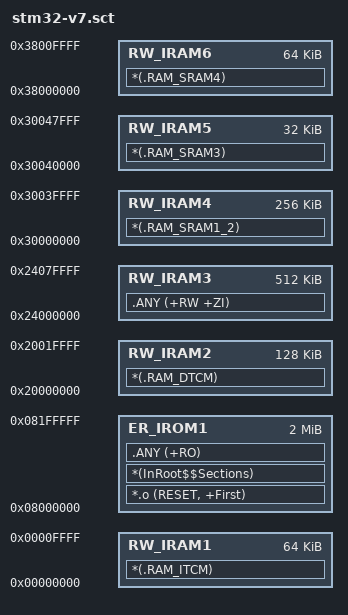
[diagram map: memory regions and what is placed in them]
; *************************************************************
; *** Scatter-Loading Description File generated by uVision ***
; *************************************************************

LR_IROM1 0x08000000 0x00200000  {    ; load region size_region
  ER_IROM1 0x08000000 0x00200000  {  ; load address = execution address
   *.o (RESET, +First)
   *(InRoot$$Sections)
   .ANY (+RO)
  }
  
  RW_IRAM1 0x00000000 0x00010000  {  ; RW data - 64KB ITCM
  
    *(.RAM_ITCM) 
  }
  
  RW_IRAM2 0x20000000 0x00020000  {  ; RW data - 128KB DTCM
   ;.ANY (+RW +ZI)
    *(.RAM_DTCM) 
  }
  
  RW_IRAM3 0x24000000 0x00080000  {  ; RW data - 512KB AXI SRAM  编译器上设定的
   ;*(.RAM_D1) 
   .ANY (+RW +ZI)
  }
  
  RW_IRAM4 0x30000000 0x00040000  {  ; RW data - 128KB SRAM1(0x30000000) + 128KB SRAM2(0x3002 0000)
   *(.RAM_SRAM1_2)
  }
  
    RW_IRAM5 0x30040000 0x00008000  {  ; RW data - 32KB SRAM3(0x30040000)
   *(.RAM_SRAM3)	;以太网的DMA描述符必须定义在SRAM3里面才可以正常工作，因此一般把SRAN3独立给以太网使用
  }
  
  
  RW_IRAM6 0x38000000 0x00010000  {  ; RW data - 64KB SRAM4(0x38000000)
   *(.RAM_SRAM4)	
  }
  
;  RW_IRAM7 0xC0000000 UNINIT 0x02000000  {  ; RW data - 32MB SDRAM(0xC0000000) 外接内存
;   *(.RAM_EX_SDRAM)
;  }
    
}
